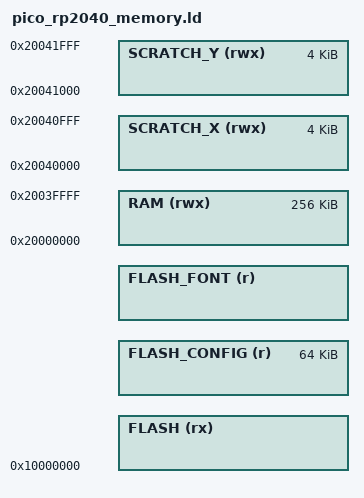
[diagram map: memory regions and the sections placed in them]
/* RP2040 memory regions (264 KiB SRAM, split as 256 + 4 + 4 KiB). */

FLASH_ORIGIN = 0x10000000;
CONFIG_LENGTH = 64K;
FLASH_OTHER_LENGTH = PRIMARY_FLASH_LENGTH - CONFIG_LENGTH - FONT_LENGTH;

MEMORY
{
    FLASH (rx)        : ORIGIN = FLASH_ORIGIN, LENGTH = FLASH_OTHER_LENGTH
    FLASH_CONFIG (r)  : ORIGIN = FLASH_ORIGIN + FLASH_OTHER_LENGTH, LENGTH = CONFIG_LENGTH
    FLASH_FONT (r)    : ORIGIN = FLASH_ORIGIN + FLASH_OTHER_LENGTH + CONFIG_LENGTH, LENGTH = FONT_LENGTH
    RAM (rwx)         : ORIGIN = 0x20000000, LENGTH = 256K
    SCRATCH_X (rwx)   : ORIGIN = 0x20040000, LENGTH = 4K
    SCRATCH_Y (rwx)   : ORIGIN = 0x20041000, LENGTH = 4K
}
